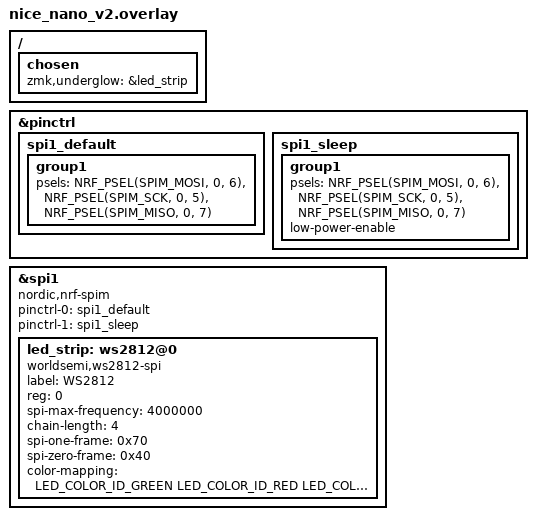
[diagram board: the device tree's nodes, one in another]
/* Copyright (c) 2021-2022 The ZMK Contributors
 * SPDX-License-Identifier: MIT
 */

#include <dt-bindings/led/led.h>

&pinctrl {
    spi1_default: spi1_default {
        group1 {
            psels = <NRF_PSEL(SPIM_MOSI, 0, 6)>,  // P0.06 (original mosi-pin)
                    <NRF_PSEL(SPIM_SCK, 0, 5)>,   // P0.05 (original sck-pin)
                    <NRF_PSEL(SPIM_MISO, 0, 7)>;  // P0.07 (original miso-pin)
        };
    };

    spi1_sleep: spi1_sleep {
        group1 {
            psels = <NRF_PSEL(SPIM_MOSI, 0, 6)>,  // P0.06 (original mosi-pin)
                    <NRF_PSEL(SPIM_SCK, 0, 5)>,   // P0.05 (original sck-pin)
                    <NRF_PSEL(SPIM_MISO, 0, 7)>;  // P0.07 (original miso-pin)
            low-power-enable;
        };
    };
};

&spi1 {
	compatible = "nordic,nrf-spim";
	status = "okay";
	pinctrl-0 = <&spi1_default>;
	pinctrl-1 = <&spi1_sleep>;
	pinctrl-names = "default";
	pinctrl-names = "default", "sleep";

	led_strip: ws2812@0 {
		compatible = "worldsemi,ws2812-spi";
		label = "WS2812";

		/* SPI */
		reg = <0>; /* ignored, but necessary for SPI bindings */
		spi-max-frequency = <4000000>;

		/* WS2812 */
		chain-length = <4>; /* arbitrary; change at will */
		spi-one-frame = <0x70>;
		spi-zero-frame = <0x40>;
                color-mapping = <LED_COLOR_ID_GREEN
                                 LED_COLOR_ID_RED
                                 LED_COLOR_ID_BLUE>;
        };
};

/ {
	chosen {
		zmk,underglow = &led_strip;
	};
};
